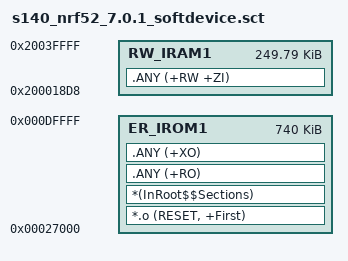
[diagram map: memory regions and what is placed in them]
; *************************************************************
; *** Scatter-Loading Description File generated by uVision ***
; *************************************************************

LR_IROM1 0x00027000 0x000B9000  {    ; load region size_region
  ER_IROM1 0x00027000 0x000B9000  {  ; load address = execution address
   *.o (RESET, +First)
   *(InRoot$$Sections)
   .ANY (+RO)
   .ANY (+XO)
  }
  RW_IRAM1 0x200018D8 0x0003E728  {  ; RW data
   .ANY (+RW +ZI)
  }
}

